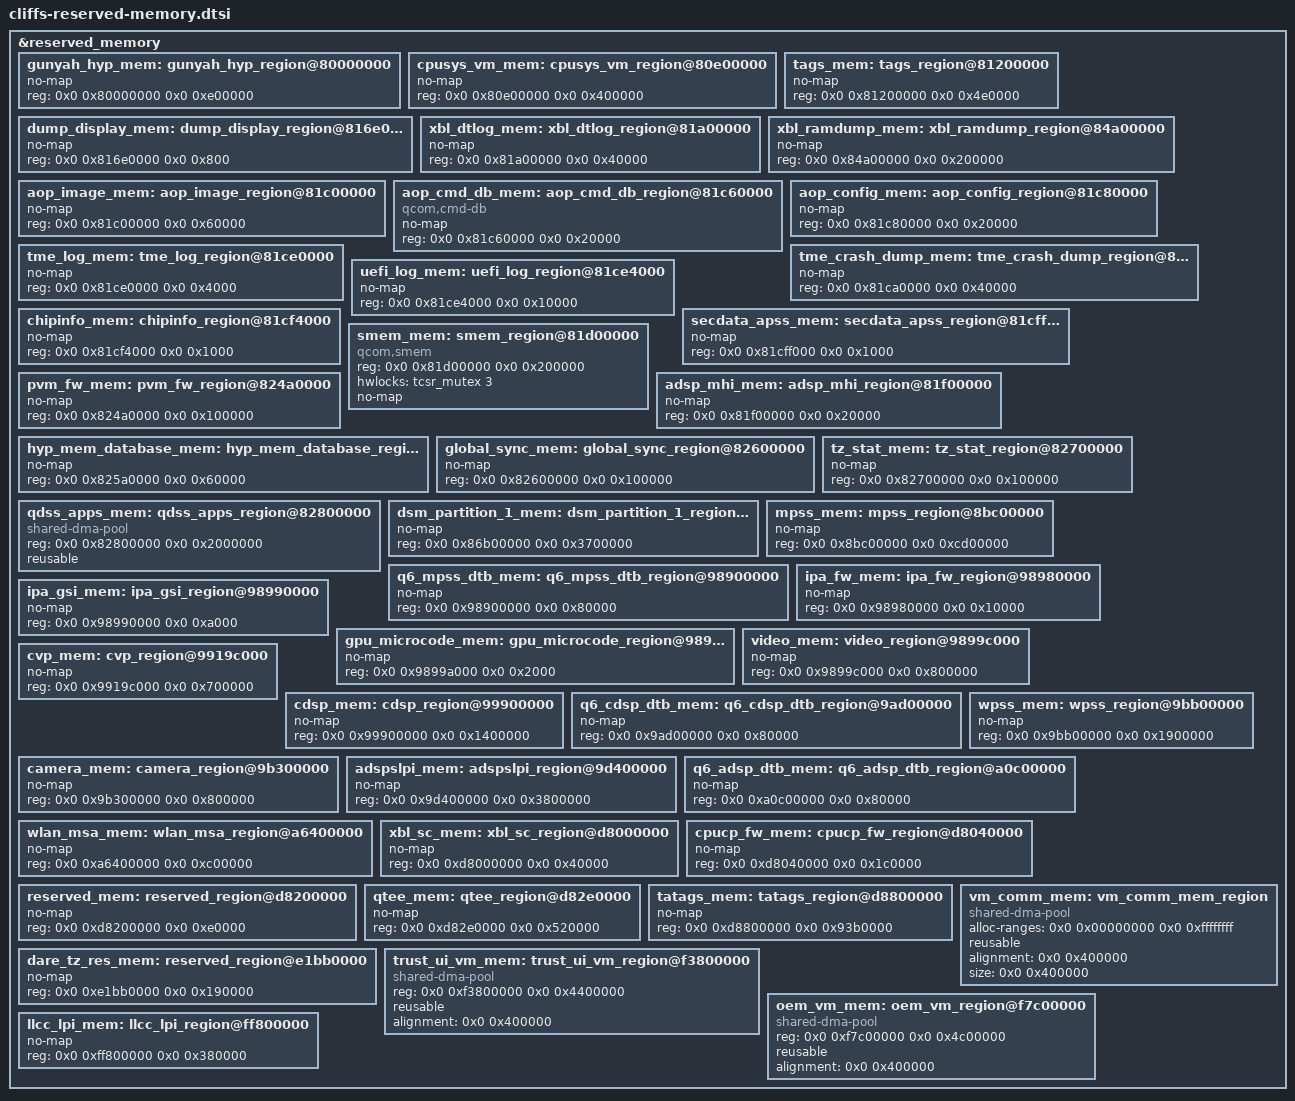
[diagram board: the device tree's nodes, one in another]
&reserved_memory {
	#address-cells = <2>;
	#size-cells = <2>;
	ranges;

	gunyah_hyp_mem: gunyah_hyp_region@80000000 {
		no-map;
		reg = <0x0 0x80000000 0x0 0xe00000>;
	};

	cpusys_vm_mem: cpusys_vm_region@80e00000 {
		no-map;
		reg = <0x0 0x80e00000 0x0 0x400000>;
	};

	tags_mem: tags_region@81200000 {
		no-map;
		reg = <0x0 0x81200000 0x0 0x4e0000>;
	};
	
	dump_display_mem: dump_display_region@816e0000 {
		no-map;
		reg = <0x0 0x816e0000 0x0 0x800>;
	};
        
	xbl_dtlog_mem: xbl_dtlog_region@81a00000 {
		no-map;
		reg = <0x0 0x81a00000 0x0 0x40000>;
	};
        
	xbl_ramdump_mem: xbl_ramdump_region@84a00000 {
		no-map;
		reg = <0x0 0x84a00000 0x0 0x200000>;
	};

	aop_image_mem: aop_image_region@81c00000 {
		no-map;
		reg = <0x0 0x81c00000 0x0 0x60000>;
	};

	aop_cmd_db_mem: aop_cmd_db_region@81c60000 {
		compatible = "qcom,cmd-db";
		no-map;
		reg = <0x0 0x81c60000 0x0 0x20000>;
	};

	aop_config_mem: aop_config_region@81c80000 {
		no-map;
		reg = <0x0 0x81c80000 0x0 0x20000>;
	};

	tme_crash_dump_mem: tme_crash_dump_region@81ca0000 {
		no-map;
		reg = <0x0 0x81ca0000 0x0 0x40000>;
	};

	tme_log_mem: tme_log_region@81ce0000 {
		no-map;
		reg = <0x0 0x81ce0000 0x0 0x4000>;
	};

	uefi_log_mem: uefi_log_region@81ce4000 {
		no-map;
		reg = <0x0 0x81ce4000 0x0 0x10000>;
	};

	chipinfo_mem: chipinfo_region@81cf4000 {
		no-map;
		reg = <0x0 0x81cf4000 0x0 0x1000>;
	};

	secdata_apss_mem: secdata_apss_region@81cff000 {
		no-map;
		reg = <0x0 0x81cff000 0x0 0x1000>;
	};

	smem_mem: smem_region@81d00000 {
		compatible = "qcom,smem";
		reg = <0x0 0x81d00000 0x0 0x200000>;
		hwlocks = <&tcsr_mutex 3>;
		no-map;
	};

	adsp_mhi_mem: adsp_mhi_region@81f00000 {
		no-map;
		reg = <0x0 0x81f00000 0x0 0x20000>;
	};

	pvm_fw_mem: pvm_fw_region@824a0000 {
		no-map;
		reg = <0x0 0x824a0000 0x0 0x100000>;
	};

	hyp_mem_database_mem: hyp_mem_database_region@825a0000 {
		no-map;
		reg = <0x0 0x825a0000 0x0 0x60000>;
	};

	global_sync_mem: global_sync_region@82600000 {
		no-map;
		reg = <0x0 0x82600000 0x0 0x100000>;
	};

	tz_stat_mem: tz_stat_region@82700000 {
		no-map;
		reg = <0x0 0x82700000 0x0 0x100000>;
	};

	qdss_apps_mem: qdss_apps_region@82800000 {
		compatible = "shared-dma-pool";
		reg = <0x0 0x82800000 0x0 0x2000000>;
		reusable;
	};

	dsm_partition_1_mem: dsm_partition_1_region@86b00000 {
		no-map;
		reg = <0x0 0x86b00000 0x0 0x3700000>;
	};

	mpss_mem: mpss_region@8bc00000 {
		no-map;
		reg = <0x0 0x8bc00000 0x0 0xcd00000>;
	};

	q6_mpss_dtb_mem: q6_mpss_dtb_region@98900000 {
		no-map;
		reg = <0x0 0x98900000 0x0 0x80000>;
	};

	ipa_fw_mem: ipa_fw_region@98980000 {
		no-map;
		reg = <0x0 0x98980000 0x0 0x10000>;
	};

	ipa_gsi_mem: ipa_gsi_region@98990000 {
		no-map;
		reg = <0x0 0x98990000 0x0 0xa000>;
	};

	gpu_microcode_mem: gpu_microcode_region@9899a000 {
		no-map;
		reg = <0x0 0x9899a000 0x0 0x2000>;
	};

	video_mem: video_region@9899c000 {
		no-map;
		reg = <0x0 0x9899c000 0x0 0x800000>;
	};

	cvp_mem: cvp_region@9919c000 {
		no-map;
		reg = <0x0 0x9919c000 0x0 0x700000>;
	};

	cdsp_mem: cdsp_region@99900000 {
		no-map;
		reg = <0x0 0x99900000 0x0 0x1400000>;
	};

	q6_cdsp_dtb_mem: q6_cdsp_dtb_region@9ad00000 {
		no-map;
		reg = <0x0 0x9ad00000 0x0 0x80000>;
	};

	camera_mem: camera_region@9b300000 {
		no-map;
		reg = <0x0 0x9b300000 0x0 0x800000>;
	};

	wpss_mem: wpss_region@9bb00000 {
		no-map;
		reg = <0x0 0x9bb00000 0x0 0x1900000>;
	};

        adspslpi_mem: adspslpi_region@9d400000 {
		no-map;
		reg = <0x0 0x9d400000 0x0 0x3800000>;
	};

        q6_adsp_dtb_mem: q6_adsp_dtb_region@a0c00000 {
		no-map;
		reg = <0x0 0xa0c00000 0x0 0x80000>;
	};

	wlan_msa_mem: wlan_msa_region@a6400000 {
		no-map;
		reg = <0x0 0xa6400000 0x0 0xc00000>;
	};
              
	xbl_sc_mem: xbl_sc_region@d8000000 {
		no-map;
		reg = <0x0 0xd8000000 0x0 0x40000>;
	};

	cpucp_fw_mem: cpucp_fw_region@d8040000 {
		no-map;
		reg = <0x0 0xd8040000 0x0 0x1c0000>;
	};

	reserved_mem: reserved_region@d8200000 {
		no-map;
		reg = <0x0 0xd8200000 0x0 0xe0000>;
	};

	qtee_mem: qtee_region@d82e0000 {
		no-map;
		reg = <0x0 0xd82e0000 0x0 0x520000>;
	};

	tatags_mem: tatags_region@d8800000 {
		no-map;
		reg = <0x0 0xd8800000 0x0 0x93b0000>;
	};

	dare_tz_res_mem: reserved_region@e1bb0000 {
		no-map;
		reg = <0x0 0xe1bb0000 0x0 0x190000>;
	};

	vm_comm_mem: vm_comm_mem_region {
		compatible = "shared-dma-pool";
		alloc-ranges = <0x0 0x00000000 0x0 0xffffffff>;
		reusable;
		alignment = <0x0 0x400000>;
		size = <0x0 0x400000>;
	};

	trust_ui_vm_mem: trust_ui_vm_region@f3800000 {
		compatible = "shared-dma-pool";
		reg = <0x0 0xf3800000 0x0 0x4400000>;
		reusable;
		alignment = <0x0 0x400000>;
	};

	oem_vm_mem: oem_vm_region@f7c00000 {
		compatible = "shared-dma-pool";
		reg = <0x0 0xf7c00000 0x0 0x4c00000>;
		reusable;
		alignment = <0x0 0x400000>;
	};

	llcc_lpi_mem: llcc_lpi_region@ff800000 {
		no-map;
		reg = <0x0 0xff800000 0x0 0x380000>;
	};

};
